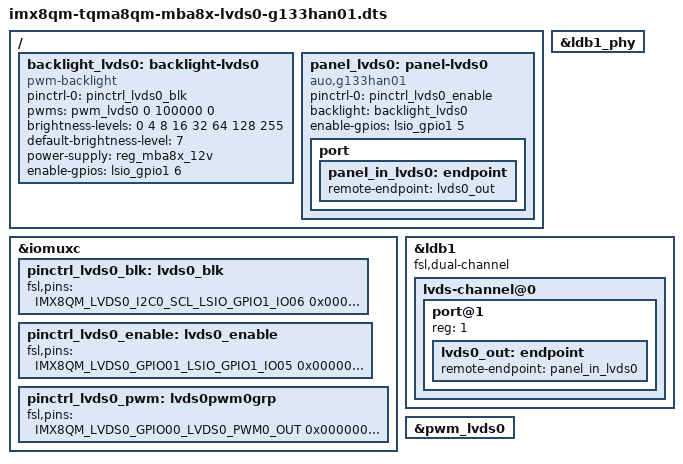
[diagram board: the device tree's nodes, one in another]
// SPDX-License-Identifier: (GPL-2.0-or-later OR MIT)
/*
 * Copyright (c) 2018-2023 TQ-Systems GmbH <linux@ew.tq-group.com>,
 * D-82229 Seefeld, Germany.
 * Author: Alexander Stein
 */
#include "imx8qm-tqma8qm-mba8x.dts"

/ {
	backlight_lvds0: backlight-lvds0 {
		compatible = "pwm-backlight";
		pinctrl-names = "default";
		pinctrl-0 = <&pinctrl_lvds0_blk>;
		pwms = <&pwm_lvds0 0 100000 0>;
		brightness-levels = <0 4 8 16 32 64 128 255>;
		default-brightness-level = <7>;
		power-supply = <&reg_mba8x_12v>;
		enable-gpios = <&lsio_gpio1 6 GPIO_ACTIVE_HIGH>;
	};

	panel_lvds0: panel-lvds0 {
		compatible = "auo,g133han01";
		pinctrl-names = "default";
		pinctrl-0 = <&pinctrl_lvds0_enable>;
		backlight = <&backlight_lvds0>;
		enable-gpios = <&lsio_gpio1 5 GPIO_ACTIVE_HIGH>;

		port {
			panel_in_lvds0: endpoint {
				remote-endpoint = <&lvds0_out>;
			};
		};
	};
};

&iomuxc {
	pinctrl_lvds0_blk: lvds0_blk {
		fsl,pins = <
			IMX8QM_LVDS0_I2C0_SCL_LSIO_GPIO1_IO06	0x00000021
		>;
	};

	pinctrl_lvds0_enable: lvds0_enable {
		fsl,pins = <
			IMX8QM_LVDS0_GPIO01_LSIO_GPIO1_IO05	0x00000021
		>;
	};

	pinctrl_lvds0_pwm: lvds0pwm0grp {
		fsl,pins = <
			IMX8QM_LVDS0_GPIO00_LVDS0_PWM0_OUT	0x00000020
		>;
	};
};

&ldb1_phy {
	status = "okay";
};

&ldb1 {
	fsl,dual-channel;
	status = "okay";

	lvds-channel@0 {
		status = "okay";

		port@1 {
			reg = <1>;

			lvds0_out: endpoint {
				remote-endpoint = <&panel_in_lvds0>;
			};
		};
	};
};

&panel_lvds0 {
	compatible = "auo,g133han01";
	status = "okay";
};

&pwm_lvds0 {
	status = "okay";
};
